AUTOSAR XML (schema 4-0-3)
standard types defined: Boolean, UInt16, UInt32
package /AUTOSAR_Platform/DataConstrs
  range DC_Boolean: raw 0..1
  range DC_UInt16: raw 0..65535
package /PATAC/MSM/ComponentTypes
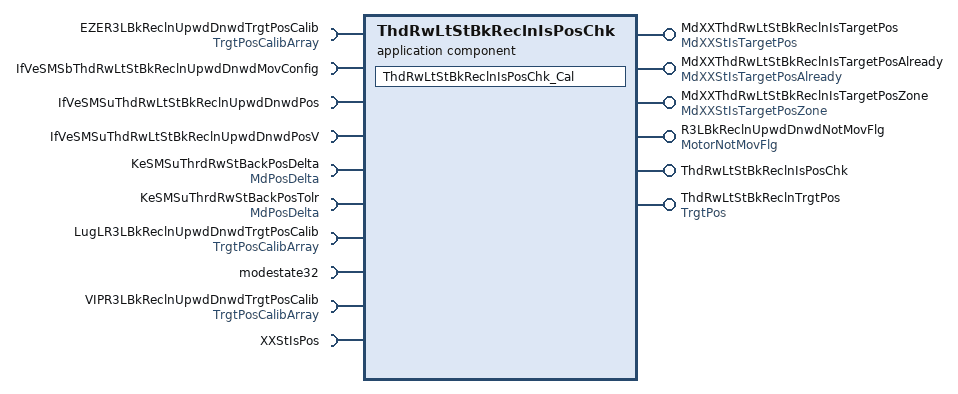
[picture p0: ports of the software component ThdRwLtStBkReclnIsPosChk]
  application sw component type ThdRwLtStBkReclnIsPosChk
    6 x provide port:
      MdXXThdRwLtStBkReclnIsTargetPos: nonqueued-sender-com-spec=data-element=MdXXStIsTargetPos/Val, provided-interface=MdXXStIsTargetPos
      MdXXThdRwLtStBkReclnIsTargetPosAlready: nonqueued-sender-com-spec=data-element=MdXXStIsTargetPosAlready/Val, provided-interface=MdXXStIsTargetPosAlready
      MdXXThdRwLtStBkReclnIsTargetPosZone: nonqueued-sender-com-spec=data-element=MdXXStIsTargetPosZone/Val, provided-interface=MdXXStIsTargetPosZone
      R3LBkReclnUpwdDnwdNotMovFlg: nonqueued-sender-com-spec{data-element=MotorNotMovFlg/Val, init-value=0}, provided-interface=MotorNotMovFlg
      ThdRwLtStBkReclnIsPosChk: server-com-spec{operation=Cal, queue-length=1}, provided-interface=ThdRwLtStBkReclnIsPosChk
      ThdRwLtStBkReclnTrgtPos: nonqueued-sender-com-spec{data-element=TrgtPos/Val, init-value=4095}, provided-interface=TrgtPos
    10 x require port:
      EZER3LBkReclnUpwdDnwdTrgtPosCalib: nonqueued-receiver-com-spec{data-element=TrgtPosArray, filter=data-filter-type=ALWAYS, init-value=[4095, 4095, 4095]}, required-interface=TrgtPosCalibArray
      IfVeSMSbThdRwLtStBkReclnUpwdDnwdMovConfig: nonqueued-receiver-com-spec{data-element=IfVeSMSbThdRwLtStBkReclnUpwdDnwdMovConfig/Val, filter=data-filter-type=ALWAYS, init-value=0}, required-interface=IfVeSMSbThdRwLtStBkReclnUpwdDnwdMovConfig
      IfVeSMSuThdRwLtStBkReclnUpwdDnwdPos: nonqueued-receiver-com-spec{data-element=IfVeSMSuThdRwLtStBkReclnUpwdDnwdPos/Val, filter=data-filter-type=ALWAYS, init-value=0}, required-interface=IfVeSMSuThdRwLtStBkReclnUpwdDnwdPos
      IfVeSMSuThdRwLtStBkReclnUpwdDnwdPosV: nonqueued-receiver-com-spec{data-element=IfVeSMSuThdRwLtStBkReclnUpwdDnwdPosV/Val, filter=data-filter-type=ALWAYS, init-value=0}, required-interface=IfVeSMSuThdRwLtStBkReclnUpwdDnwdPosV
      KeSMSuThrdRwStBackPosDelta: parameter-require-com-spec{init-value=150, parameter=Val}, required-interface=MdPosDelta
      KeSMSuThrdRwStBackPosTolr: parameter-require-com-spec{init-value=150, parameter=Val}, required-interface=MdPosDelta
      LugLR3LBkReclnUpwdDnwdTrgtPosCalib: nonqueued-receiver-com-spec{data-element=TrgtPosArray, filter=data-filter-type=ALWAYS, init-value=[4095, 4095, 4095]}, required-interface=TrgtPosCalibArray
      modestate32: nonqueued-receiver-com-spec{data-element=modestate32/Val, filter=data-filter-type=ALWAYS, init-value=0}, required-interface=modestate32
      VIPR3LBkReclnUpwdDnwdTrgtPosCalib: nonqueued-receiver-com-spec{data-element=TrgtPosArray, filter=data-filter-type=ALWAYS, init-value=[4095, 4095, 4095]}, required-interface=TrgtPosCalibArray
      XXStIsPos: client-com-spec=Get, required-interface=XXStIsPos
    behavior ThdRwLtStBkReclnIsPosChk_InternalBehavior
      operation invoked event OIT_ThdRwLtStBkReclnIsPosChk_Cal_ThdRwLtStBkReclnIsPosChk_Cal: start-on-event=ThdRwLtStBkReclnIsPosChk_Cal, operation=ThdRwLtStBkReclnIsPosChk.Cal
      runnable ThdRwLtStBkReclnIsPosChk_Cal
        data-receive-point-by-arguments:
          7 x access:
            REC_EZER3LBkReclnUpwdDnwdTrgtPosCalib_TrgtPosArray: accessed-variable=EZER3LBkReclnUpwdDnwdTrgtPosCalib.TrgtPosArray
            REC_IfVeSMSbThdRwLtStBkReclnUpwdDnwdMovConfig_Val: accessed-variable=IfVeSMSbThdRwLtStBkReclnUpwdDnwdMovConfig.Val
            REC_IfVeSMSuThdRwLtStBkReclnUpwdDnwdPos_Val: accessed-variable=IfVeSMSuThdRwLtStBkReclnUpwdDnwdPos.Val
            REC_IfVeSMSuThdRwLtStBkReclnUpwdDnwdPosV_Val: accessed-variable=IfVeSMSuThdRwLtStBkReclnUpwdDnwdPosV.Val
            REC_LugLR3LBkReclnUpwdDnwdTrgtPosCalib_TrgtPosArray: accessed-variable=LugLR3LBkReclnUpwdDnwdTrgtPosCalib.TrgtPosArray
            REC_modestate32_Val: accessed-variable=modestate32.Val
            REC_VIPR3LBkReclnUpwdDnwdTrgtPosCalib_TrgtPosArray: accessed-variable=VIPR3LBkReclnUpwdDnwdTrgtPosCalib.TrgtPosArray
        data-send-points:
          5 x access:
            SEND_MdXXThdRwLtStBkReclnIsTargetPos_Val: accessed-variable=MdXXThdRwLtStBkReclnIsTargetPos.Val
            SEND_MdXXThdRwLtStBkReclnIsTargetPosAlready_Val: accessed-variable=MdXXThdRwLtStBkReclnIsTargetPosAlready.Val
            SEND_MdXXThdRwLtStBkReclnIsTargetPosZone_Val: accessed-variable=MdXXThdRwLtStBkReclnIsTargetPosZone.Val
            SEND_R3LBkReclnUpwdDnwdNotMovFlg_Val: accessed-variable=R3LBkReclnUpwdDnwdNotMovFlg.Val
            SEND_ThdRwLtStBkReclnTrgtPos_Val: accessed-variable=ThdRwLtStBkReclnTrgtPos.Val
        parameter access PA_KeSMSuThrdRwStBackPosDelta_Val: accessed-parameter=KeSMSuThrdRwStBackPosDelta.Val
        parameter access PA_KeSMSuThrdRwStBackPosTolr_Val: accessed-parameter=KeSMSuThrdRwStBackPosTolr.Val
        sync call SC_XXStIsPos_Get: operation=XXStIsPos.Get, timeout=0
  swc implementation ThdRwLtStBkReclnIsPosChk_Implementation: behavior=ThdRwLtStBkReclnIsPosChk_InternalBehavior
    code-descriptors:
      code Default: artifact-descriptors=autosar-engineering-object={short-label=Default, category=SWSRC}
package /PATAC/MSM/ModeAdjust/CalPortInterface
  parameter interface MdPosDelta
    parameter data prototype Val: sw-calibration-access=READ-WRITE, type=UInt16
package /PATAC/MSM/ModeAdjust/DataType
  impl type TrgtPosCalibArray: category=ARRAY, sw-calibration-access=READ-ONLY, type-emitter=RTE  # 0:pos 1:max 2:min
    element Element: array-size=3, array-size-semantics=FIXED-SIZE, implementation-data-type=UInt16, invalid-value=0
package /PATAC/MSM/ModeAdjust/Interfaces
  sender receiver interface IfVeSMSuThdRwLtStBkReclnUpwdDnwdPosV: invalidation-policy{data-element=IfVeSMSuThdRwLtStBkReclnUpwdDnwdPosV/Val, handle-invalid=DONT-INVALIDATE}
    data Val: type=Implementation/Boolean
package /PATAC/MSM/ModeAdjust/PortInterface
  client server interface ThdRwLtStBkReclnIsPosChk
    operation Cal
  client server interface XXStIsPos
    operation Get
      8 x arg, all with server-argument-impl-policy=USE-ARGUMENT-TYPE:
        PosV: type=DataTypes/Boolean, direction=IN
        Pos: type=UInt16, direction=IN
        CalibArray: type=TrgtPosCalibArray, direction=IN
        Delta: type=UInt16, direction=IN
        Tolr: type=UInt16, direction=IN
        IsPos: type=DataTypes/Boolean, direction=OUT
        IsPosZone: type=DataTypes/Boolean, direction=OUT
        IsPosAlready: type=DataTypes/Boolean, direction=OUT
  6 x sender receiver interface:
    MdXXStIsTargetPos: invalidation-policy{data-element=MdXXStIsTargetPos/Val, handle-invalid=DONT-INVALIDATE}
      data Val: type=UInt32
    MdXXStIsTargetPosAlready: invalidation-policy{data-element=MdXXStIsTargetPosAlready/Val, handle-invalid=DONT-INVALIDATE}
      data Val: type=UInt32
    MdXXStIsTargetPosZone: invalidation-policy{data-element=MdXXStIsTargetPosZone/Val, handle-invalid=DONT-INVALIDATE}
      data Val: type=UInt32
    modestate32: invalidation-policy{data-element=modestate32/Val, handle-invalid=DONT-INVALIDATE}
      data Val: type=UInt32
    MotorNotMovFlg: invalidation-policy{data-element=MotorNotMovFlg/Val, handle-invalid=DONT-INVALIDATE}
      data Val: type=Implementation/Boolean
    TrgtPosCalibArray: invalidation-policy{data-element=TrgtPosArray, handle-invalid=DONT-INVALIDATE}
      data TrgtPosArray: type=TrgtPosCalibArray  # 0:Pos 1:Max 2:Min
package /PATAC/MSM/PortInterfaces
  sender receiver interface IfVeSMSbThdRwLtStBkReclnUpwdDnwdMovConfig: invalidation-policy{data-element=IfVeSMSbThdRwLtStBkReclnUpwdDnwdMovConfig/Val, handle-invalid=DONT-INVALIDATE}
    data Val: type=Implementation/Boolean
  sender receiver interface IfVeSMSuThdRwLtStBkReclnUpwdDnwdPos: invalidation-policy{data-element=IfVeSMSuThdRwLtStBkReclnUpwdDnwdPos/Val, handle-invalid=DONT-INVALIDATE}
    data Val: type=UInt16
  sender receiver interface TrgtPos: invalidation-policy{data-element=TrgtPos/Val, handle-invalid=DONT-INVALIDATE}
    data Val: type=UInt16
